# STM32H503 register map
File version: 1.5
CPU: CM33 r0p0, little endian, MPU, FPU, 4 interrupt priority bits
Registers are 32-bit, read-write, reset 0x0 unless marked. A register's access mark holds for its fields unless they carry their own. Offsets are from the block's base; [hi:lo] are bit positions.

## OPAMP1 — Operational amplifiers
Base 0x40003400
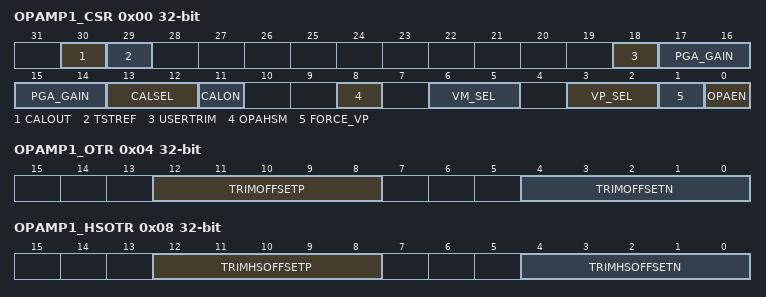
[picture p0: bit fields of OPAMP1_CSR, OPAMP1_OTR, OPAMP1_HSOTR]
0x00 OPAMP1_CSR access per field — OPAMP1 control/status register
  [30] CALOUT ro — Operational amplifier calibration output OPAMP output status flag. During the calibration mode, OPAMP is used as comparator.
  [29] TSTREF rw — OPAMP calibration reference voltage output control (reserved for test)
  [18] USERTRIM rw — User trimming enable This bit allows to switch from 'factory' AOP offset trimmed values to 'user' AOP offset trimmed values This bit is active for both mode normal and high-power.
  [17:14] PGA_GAIN rw — Operational amplifier Programmable amplifier gain value
  [13:12] CALSEL rw — Calibration selection It is used to select the offset calibration bus used to generate the internal reference voltage when CALON = 1 or FORCE_VP= 1.
  [11] CALON rw — Calibration mode enabled
  [8] OPAHSM rw — Operational amplifier high-speed mode The operational amplifier must be disable to change this configuration.
  [6:5] VM_SEL rw — Inverting input selection
  [3:2] VP_SEL rw — Non inverted input selection
  [1] FORCE_VP rw — Force internal reference on VP (reserved for test)
  [0] OPAEN rw — Operational amplifier Enable Note: If OPAMP1 is unconnected in a specific package, it must remain disabled (keep OPAMP1_CSR register default value).
0x04 OPAMP1_OTR (reset mask 0xFFFF0000) — OPAMP1 trimming register in normal mode
  [12:8] TRIMOFFSETP — Trim for PMOS differential pairs
  [4:0] TRIMOFFSETN — Trim for NMOS differential pairs
0x08 OPAMP1_HSOTR (reset mask 0xFFFF0000) — OPAMP1 trimming register in high-speed mode
  [12:8] TRIMHSOFFSETP — High-speed mode trim for PMOS differential pairs
  [4:0] TRIMHSOFFSETN — High-speed mode trim for NMOS differential pairs
0x0C OPAMP_OR access not given — OPAMP option register

## WWDG — System window watchdog
Base 0x40002C00
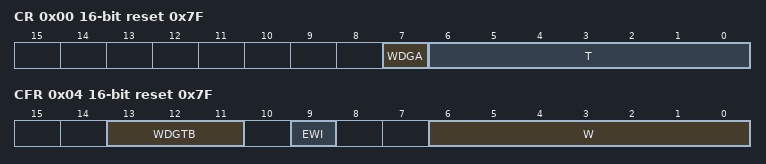
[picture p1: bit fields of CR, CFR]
0x00 CR 16-bit reset 0x7F — WWDG control register
  [7] WDGA — Activation bit This bit is set by software and only cleared by hardware after a reset. When WDGA = 1, the watchdog can generate a reset.
    0=Disabled (Watchdog disabled); 1=Enabled (Watchdog enabled)
  [6:0] T — 7-bit counter (MSB to LSB) These bits contain the value of the watchdog counter, decremented every (4096 x 2WDGTB[2:0]) PCLK cycles. A reset is produced when it is decremented from 0x40 to 0x3F (T6 becomes cleared).
0x04 CFR 16-bit access not given reset 0x7F — WWDG configuration register
  [13:11] WDGTB — Timer base The timebase of the prescaler can be modified as follows:
    0=Div1 (Counter clock (PCLK1 div 4096) div 1); 1=Div2 (Counter clock (PCLK1 div 4096) div 2); 2=Div4 (Counter clock (PCLK1 div 4096) div 4); 3=Div8 (Counter clock (PCLK1 div 4096) div 8); 4=Div16 (Counter clock (PCLK1 div 4096) div 16); 5=Div32 (Counter clock (PCLK1 div 4096) div 32); 6=Div64 (Counter clock (PCLK1 div 4096) div 64); 7=Div128 (Counter clock (PCLK1 div 4096) div 128)
  [9] EWI rw — Early wakeup interrupt When set, an interrupt occurs whenever the counter reaches the value 0x40. This interrupt is only cleared by hardware after a reset.
    on write: 1=Enable (interrupt occurs whenever the counter reaches the value 0x40)
  [6:0] W rw — 7-bit window value These bits contain the window value to be compared with the down-counter.
0x08 SR 16-bit — WWDG status register
  [0] EWIF write-0-clears — Early wakeup interrupt flag This bit is set by hardware when the counter has reached the value 0x40. It must be cleared by software by writing '0'. Writing '1' has no effect. This bit is also set if the interrupt is not enabled.
    on read: 0=Finished (The EWI Interrupt Service Routine has been serviced); 1=Pending (The EWI Interrupt Service Routine has been triggered) | on write: 0=Finished (The EWI Interrupt Service Routine has been serviced)
